VERSION ""

NS_ :

BS_:

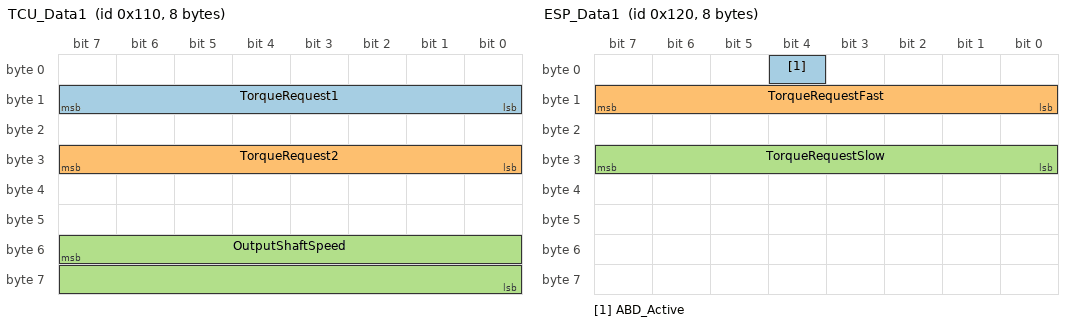
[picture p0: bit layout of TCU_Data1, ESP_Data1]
BO_ 272 TCU_Data1: 8 TCU
 SG_ TorqueRequest1 : 15|8@0+ (1,0) [0|255] ""  ABS,ESP,ECU
 SG_ TorqueRequest2 : 31|8@0+ (1,0) [0|255] ""  ABS,ESP,ECU
 SG_ OutputShaftSpeed : 55|16@0+ (1,0) [0|65535] "rpm"  ABS,ESP,ECU

BO_ 288 ESP_Data1: 8 ESP
 SG_ ABD_Active : 4|1@0+ (1,0) [0|1] "yes/no"  ECU,TCU
 SG_ TorqueRequestFast : 15|8@0+ (1,0) [0|255] ""  ECU,TCU
 SG_ TorqueRequestSlow : 31|8@0+ (1,0) [0|255] ""  ECU,TCU

BO_ 384 SAS_Data: 8 SAS
 SG_ SteeringAngle : 0|16@1- (0.1,0) [-3276.8|3276.7] "yes/no"  ECU,TCU
 SG_ SteeringSpeed : 16|8@1+ (1,0) [0|255] ""  ECU,TCU

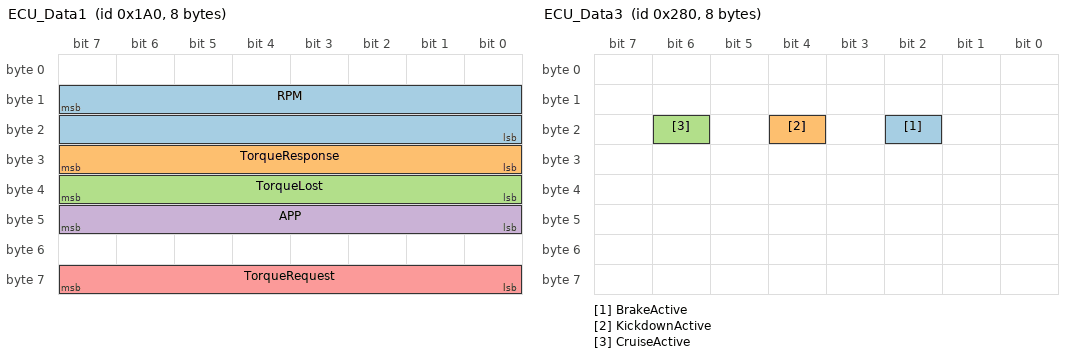
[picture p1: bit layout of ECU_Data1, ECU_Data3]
BO_ 416 ECU_Data1: 8 ECU
 SG_ RPM : 15|16@0+ (1,0) [0|65535] "rpm"  ABS,ESP,TCU
 SG_ TorqueResponse : 31|8@0+ (1,0) [0|255] ""  ABS,ESP,TCU
 SG_ TorqueLost : 39|8@0+ (1,0) [0|255] ""  ABS,ESP,TCU
 SG_ APP : 47|8@0+ (1,0) [0|102] ""  ABS,ESP,TCU
 SG_ TorqueRequest : 63|8@0+ (1,0) [0|255] ""  ABS,ESP,TCU

BO_ 448 ECU_Data2: 8 ECU
 SG_ TPS : 23|8@0+ (1,0) [0|100] ""  ABS,ESP,TCU

BO_ 640 ECU_Data3: 8 ECU
 SG_ BrakeActive : 18|1@0+ (1,0) [0|1] "yes/no"  ABS,ESP,TCU
 SG_ KickdownActive : 20|1@0+ (1,0) [0|1] "yes/no"  ABS,ESP,TCU
 SG_ CruiseActive : 22|1@0+ (1,0) [0|1] "yes/no"  ABS,ESP,TCU

BO_ 736 TCU_Data2: 8 TCU
 SG_ TOT : 31|8@0- (1,-40) [-40|215] ""  ECU
 SG_ InputShaftSpeed : 47|16@0+ (1,0) [0|65535] "rpm"  ECU

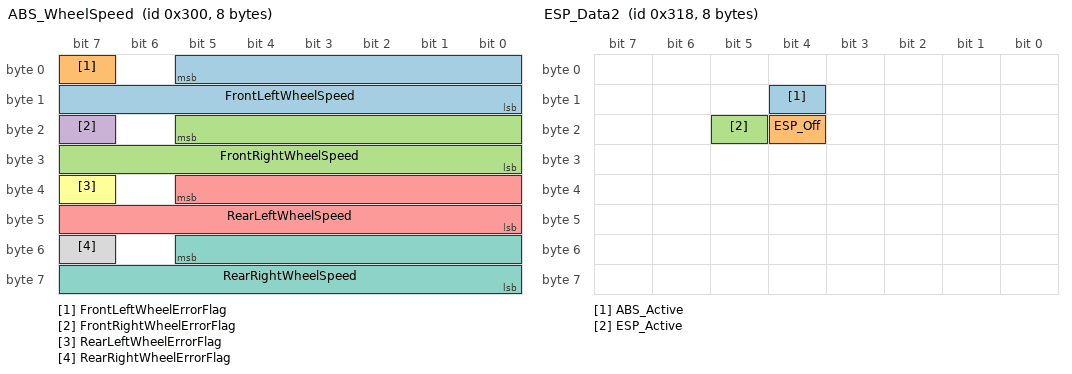
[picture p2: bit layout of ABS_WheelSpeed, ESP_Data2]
BO_ 768 ABS_WheelSpeed: 8 ABS
 SG_ FrontLeftWheelSpeed : 5|14@0+ (0.112,0) [0|255] "km/h"  ECU,TCU
 SG_ FrontLeftWheelErrorFlag : 7|1@0+ (1,0) [0|1] ""  ECU,TCU
 SG_ FrontRightWheelSpeed : 21|14@0+ (0.112,0) [0|255] "km/h"  ECU,TCU
 SG_ FrontRightWheelErrorFlag : 23|1@0+ (1,0) [0|1] ""  ECU,TCU
 SG_ RearLeftWheelSpeed : 37|14@0+ (0.112,0) [0|255] "km/h"  ECU,TCU
 SG_ RearLeftWheelErrorFlag : 39|1@0+ (1,0) [0|1] ""  ECU,TCU
 SG_ RearRightWheelSpeed : 53|14@0+ (0.112,0) [0|255] "km/h"  ECU,TCU
 SG_ RearRightWheelErrorFlag : 55|1@0+ (1,0) [0|1] ""  ECU,TCU

BO_ 792 ESP_Data2: 8 ESP
 SG_ ABS_Active : 12|1@0+ (1,0) [0|1] "yes/no"  ECU,TCU
 SG_ ESP_Off : 20|1@0+ (1,0) [0|1] "yes/no"  ECU,TCU
 SG_ ESP_Active : 21|1@0+ (1,0) [0|1] "yes/no"  ECU,TCU

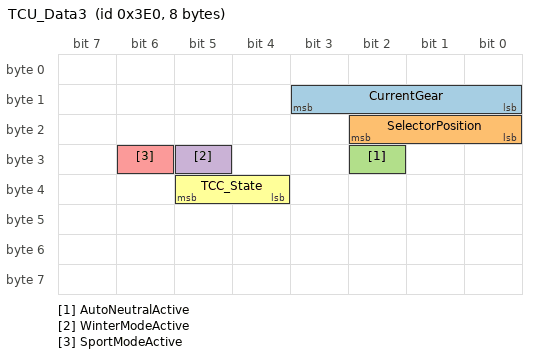
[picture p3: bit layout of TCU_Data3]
BO_ 992 TCU_Data3: 8 TCU
 SG_ CurrentGear : 11|4@0+ (1,0) [0|15] ""  ECU
 SG_ SelectorPosition : 18|3@0+ (1,0) [0|7] ""  ECU
 SG_ AutoNeutralActive : 26|1@0+ (1,0) [0|1] "yes/no"  ECU
 SG_ WinterModeActive : 29|1@0+ (1,0) [0|1] "yes/no"  ECU
 SG_ SportModeActive : 30|1@0+ (1,0) [0|1] "yes/no"  ECU
 SG_ TCC_State : 37|2@0+ (1,0) [0|2] ""  ECU

BO_ 1472 ECU_Data4: 8 ECU
 SG_ ECT : 15|8@0- (1,-40) [-40|215] ""  TCU
 SG_ IAT : 47|8@0- (1,-40) [-40|215] ""  TCU

BU_: PowertrainControlModule InstrumentCluster ElectricPowerSteering AntilockBrakeSystem

CM_ "AUTOGENERATED FILE, DO NOT EDIT";

CM_ "Imported file _comma.dbc starts here";
CM_ "BO_ STEERING_IPAS_COMMA: Copy of msg 614 so we can do angle control while the Park Assist ECU is connected (Panda spoofs 614 with 359 on connector J70). Note that addresses 0x266 and 0x167 are checksum-invariant";

CM_ "BO_ SECONDARY_STEER_ANGLE: ZSS is a high-precision steering angle sensor that can replace the lower resolution sensor in most TSS1 Toyotas. Learn more: https://github.com/commaai/openpilot/wiki/Toyota-Lexus#zorro-steering-sensor-zss";

CM_ "BO_ SDSU: The sDSU is a modified DSU for use in TSS1 Toyotas. Learn more: https://github.com/wocsor/panda/tree/smart_dsu";
CM_ SG_ 767 FD_BUTTON "The follow distance button signal as forwarded by the sdsu";

CM_ "Imported file _toyota_2017.dbc starts here";
CM_ SG_ 36 YAW_RATE "verify";
CM_ SG_ 36 ACCEL_X "x-axis accel";
CM_ SG_ 37 STEER_FRACTION "1/15th of the signal STEER_ANGLE, which is 1.5 deg; note that 0x8 is never set";
CM_ SG_ 37 STEER_RATE "factor is tbd";
CM_ SG_ 466 NEUTRAL_FORCE "force in newtons the engine/electric motors are applying without any acceleration commands or user input";
CM_ SG_ 466 ACC_BRAKING "whether brakes are being actuated from ACC command";
CM_ SG_ 466 ACCEL_NET "net acceleration produced by the system, given ACCEL_CMD, road grade and other factors";
CM_ SG_ 466 CRUISE_STATE "Active state is 8, if standstill is requested will switch to state 11(3 sec timer), after timer is elapsed will switch into state 7(standstill). If plus button was pressed - status 9, minus button pressed - status 10";
CM_ SG_ 467 ACC_FAULTED "1 when ACC is faulted and the PCM disallows engagement";
CM_ SG_ 467 SET_SPEED "43 km/h are shown as 28 mph, so conversion isn't perfect";
CM_ SG_ 467 LOW_SPEED_LOCKOUT "in low speed lockout, system would always disengage below 28mph";
CM_ SG_ 560 BRAKE_PRESSED "another brake pressed?";
CM_ SG_ 581 GAS_PEDAL "it seems slightly filtered";
CM_ SG_ 608 STEER_TORQUE_DRIVER "driver torque";
CM_ SG_ 608 STEER_OVERRIDE "set when driver torque exceeds a certain value";
CM_ SG_ 614 ANGLE "set to measured angle when ipas control isn't active";
CM_ SG_ 643 _COUNTER "only used on cars that use this msg for cruise control";
CM_ SG_ 643 BRAKE_STATUS "only used on cars that use this msg for cruise control";
CM_ SG_ 643 PRECOLLISION_ACTIVE "set 0.5s before any braking";
CM_ SG_ 835 ACC_TYPE "if 2, car is likely to have a permanent low speed lockout. 1 is ok";
CM_ SG_ 835 RADAR_DIRTY "Display Clean Radar Sensor message on HUD";
CM_ SG_ 835 ACC_MALFUNCTION "display ACC fault on dash if set to 1";
CM_ SG_ 835 ACC_CUT_IN "Display blinking yellow lead if set to 1";
CM_ SG_ 835 DISTANCE "Cycle through ACC following distance from long, mid, short when set to 1";
CM_ SG_ 835 ITS_CONNECT_LEAD "Displayed when lead car is capable of ITS Connect";
CM_ SG_ 835 ALLOW_LONG_PRESS "Enable Toyota's factory set speed increment behaviour, available on both metrics cars and imperial unit cars";
CM_ SG_ 835 PERMIT_BRAKING "Original ACC has this going high when a car in front is detected. In openpilot and before the PERMIT_BRAKING name, this was 'SET_ME_1' and is hardcoded to be high. Unsure if only informational or has an effect though existing usage in openpilot is to always set it to 1. Originally 'PMTBRKG' in the leaked toyota_2017_ref_pt.dbc file and name expansion speculated to be PerMiT BRaKinG.";
CM_ SG_ 835 ACCEL_CMD_ALT "Copy of main ACCEL_CMD, but across 8 bits instead of 16 bits like ACCEL_CMD. Unsure if only informational or has an effect. Likely informational as existing openpilot sets this to 0 and no loss of functionality observed. Originally 'AT_RAW' in leaked toyota_2017_ref_pt.dbc file.";
CM_ SG_ 865 GAS_PEDAL_ALT "copy of main GAS_PEDAL. Both use 8 bits. Might indicate that this message is for pedals.";
CM_ SG_ 865 CLUTCH_RELEASED "boolean of clutch for 6MT.";
CM_ SG_ 865 ACC_FAULTED "1 when ACC is faulted and the PCM disallows engagement. Also describes a lockout when the ACC_CONTROL->ACC_MALFUNCTION bit is set.";
CM_ SG_ 921 UI_SET_SPEED "set speed shown in the vehicle's UI with the vehicle's unit";
CM_ SG_ 921 TEMP_ACC_FAULTED "1 when the UI is displaying or playing fault-related alerts or sounds. Also 1 when pressing main on.";
CM_ SG_ 951 BRAKE_LIGHTS_ACC "brake lights when ACC commands decel";
CM_ SG_ 956 GEAR "on 6MT, only R shows.";
CM_ SG_ 1009 UI_SET_SPEED "units seem to be whatever the car is set to";
CM_ SG_ 1041 PCS_INDICATOR "Pre-Collision System Indicator";
CM_ SG_ 1041 PCS_SENSITIVITY "Pre-Collision System Sensitivity";
CM_ SG_ 1041 PCS_DUST "alert: Front Camera Low Visibility Unavailable See Owner's Manual";
CM_ SG_ 1041 PCS_DUST2 "alert: Pre-Collision System Radar Sensor Blocked Unavailable Clean Radar Sensor";
CM_ SG_ 1041 PCS_TEMP "alert: Front Camera Out of Temperature Range Unavailable Wait until Normal Temperature";
CM_ SG_ 1041 PCS_TEMP2 "alert: Pre-Collision System Out of Temperature Range Unavailable See Owner's Manual";
CM_ SG_ 1041 FRD_ADJ "alert: ERROR ADJUSTING FRONT RADAR BEAM";
CM_ SG_ 1042 LDA_SA_TOGGLE "LDA Steering Assist Toggle";
CM_ SG_ 1042 LDW_EXIST "Unclear what this is, it's usually set to 0";
CM_ SG_ 1042 LDA_SENSITIVITY "LDA Sensitivity";
CM_ SG_ 1042 LDA_ON_MESSAGE "Display LDA Turned ON message";
CM_ SG_ 1042 REPEATED_BEEPS "LDA audible warning";
CM_ SG_ 1042 LDA_UNAVAILABLE_QUIET "LDA toggles and sensitivity settings are greyed out if set to 1";
CM_ SG_ 1042 LDA_MESSAGES "Various LDA Messages";
CM_ SG_ 1042 LDA_FRONT_CAMERA_BLOCKED "originally LDAFCVB, LDA related settings are greyed out if set to 1";
CM_ SG_ 1042 TAKE_CONTROL "Please Control Steering Wheel warning";
CM_ SG_ 1042 LANE_SWAY_TOGGLE "Lane Sway Warning System SWS Switch";
CM_ SG_ 1042 LANE_SWAY_WARNING "Lane Sway Warning System Triggered";
CM_ SG_ 1042 LANE_SWAY_FLD "Unknown signal for Lane Sway Warning System, set to 7 on stock system when SWS is enabled, 0 when SWS is disabled";
CM_ SG_ 1042 LANE_SWAY_BUZZER "Similar to TWO_BEEPS";
CM_ SG_ 1042 SET_ME_X01 "empty bit on leaked dbc, always set to 1 during normal operations";
CM_ SG_ 1042 SET_ME_X02 "empty bit on leaked dbc, always set to 2 during normal operations";
CM_ SG_ 1083 STATE "when the dashboard button is pressed, the value changes from zero to non-zero";
CM_ SG_ 1161 SPDVAL1 "Numbers 0-199 is displayed, 200-254 displays circle without number and 255 is for no limit.";
CM_ SG_ 1161 SYNCID1 "counter from 1 to f at 1 Hz";
CM_ SG_ 1161 SPDVAL2 "conditional speed value 70";
CM_ SG_ 1162 SGNNUMP "1 if SPDVAL1 is set, otherwise 0";
CM_ SG_ 1162 SYNCID2 "counter from 1 to f at 1 Hz";
CM_ SG_ 1163 TSREQPD "always 1";
CM_ SG_ 1163 TSRMSW "always 1";
CM_ SG_ 1163 OTSGNNTM "always 3";
CM_ SG_ 1163 NTLVLSPD "always 3";
CM_ SG_ 1163 OVSPNTM "always 3";
CM_ SG_ 1163 OVSPVALL "-5 at start then 2 after 2 seconds";
CM_ SG_ 1163 OVSPVALM "-5 at start then 5 after 2 seconds";
CM_ SG_ 1163 OVSPVALH "-5 at start then 10 after 2 seconds";
CM_ SG_ 1163 TSRSPU "always 1";
CM_ SG_ 1552 UI_SPEED "Does not appear to match dash";
CM_ SG_ 1552 METER_SLIDER_BRIGHTNESS_PCT "Combination display brightness setting, scales from 12 per cent to 100 per cent, reflects combination meter settings only, not linked with headlight state";
CM_ SG_ 1552 METER_SLIDER_LOW_BRIGHTNESS "Combination display low brightness mode, also controls footwell lighting";
CM_ SG_ 1552 METER_SLIDER_DIMMED "Combination display slider not at max, reflects combination meter settings only, not linked with headlight state";
CM_ SG_ 1553 ODOMETER "Unit is dependent upon units signal";
CM_ SG_ 1592 LOCK_STATUS_CHANGED "1 on rising edge of lock/unlocking";
CM_ SG_ 1592 LOCK_STATUS "The next 3 bits always seem to follow this signal.";
CM_ SG_ 1592 LOCKED_VIA_KEYFOB "1 for as long as car is locked with key fob or door handle touch";

CM_ "toyota_nodsu_pt.dbc starts here";

CM_ SG_ 401 PERCENTAGE "driver override percentage (0-100), very close to steeringPressed in OP";
CM_ SG_ 401 TORQUE_WIND_DOWN "used to wind down torque on user override";
CM_ SG_ 401 ANGLE "angle of car relative to lane center on LTA camera";
CM_ SG_ 401 STEER_ANGLE_CMD "desired angle, OEM steers up to 95 degrees, no angle limit but torque will bottom out";
CM_ SG_ 401 CLEAR_HOLD_STEERING_ALERT "set to 1 when user clears LKAS_HUD->LDA_ALERT ('Hold Steering') by applying torque to steering wheel";
CM_ SG_ 401 STEER_REQUEST "enable bit for steering, 1 to steer, 0 to not";
CM_ SG_ 401 STEER_REQUEST_2 "enable bit for steering, 1 to steer, 0 to not";
CM_ SG_ 401 LKA_ACTIVE "1 when using LTA for LKA";
CM_ SG_ 401 SETME_X1 "usually 1, seen at 0 on some South American Corollas indicating lack of stock Lane Tracing Assist";
CM_ SG_ 401 SETME_X3 "almost completely correlates with Toyota Safety Sense version, but may instead describe max torque when using LTA. if TSS 2.5 or 2022 RAV4, this is always 1. if TSS 2.0 this is always 3 (or 0 on Alphard, Highlander, NX)";
CM_ SG_ 550 BRAKE_PRESSURE "seems prop to pedal force";
CM_ SG_ 550 BRAKE_POSITION "seems proportional to pedal displacement, unclear the max value of 0x1c8";
CM_ SG_ 610 TYPE "seems 1 on Corolla, 0 on all others";
CM_ SG_ 881 GAS_PEDAL "not set on all cars, only seen on TSS 2.5 Camry Hybrid so far";
CM_ SG_ 881 STEER_ANGLE "matches STEER_TORQUE_SENSOR->STEER_ANGLE";
CM_ SG_ 881 TURN_SIGNALS "flipped on some cars";
CM_ SG_ 881 LDA_SA_TOGGLE "not applicable for all cars";
CM_ SG_ 881 LTA_STEER_REQUEST "only applicable for TSS 2.5: matches STEERING_LTA->STEER_REQUEST";
CM_ SG_ 881 UNKNOWN "related to steering wheel angle";
CM_ SG_ 881 STEERING_PRESSED "only applicable for TSS 2.5: low sensitivity steering wheel pressed by driver signal";
CM_ SG_ 1014 L_ADJACENT "vehicle adjacent left side of car. enabled above 10mph, regardless of ADJACENT_ENABLED or APPROACHING_ENABLED";
CM_ SG_ 1014 L_APPROACHING "vehicle approaching from left side of car. enabled above 10mph, regardless of ADJACENT_ENABLED or APPROACHING_ENABLED";
CM_ SG_ 1014 R_ADJACENT "vehicle adjacent right side of car. enabled above 10mph, regardless of ADJACENT_ENABLED or APPROACHING_ENABLED";
CM_ SG_ 1014 R_APPROACHING "vehicle approaching from right side of car. enabled above 10mph, regardless of ADJACENT_ENABLED or APPROACHING_ENABLED";
CM_ SG_ 1014 ADJACENT_ENABLED "when BSM is enabled in settings, this is on along with APPROACHING_ENABLED. this controls bsm alert visibility";
CM_ SG_ 1014 APPROACHING_ENABLED "when BSM is enabled in settings, this is on along with ADJACENT_ENABLED. this controls bsm alert visibility";

VAL_ 544 AEB_Status 12 "AEB related" 8 "AEB actuation" 4 "AEB related" 0 "No AEB actuation";
